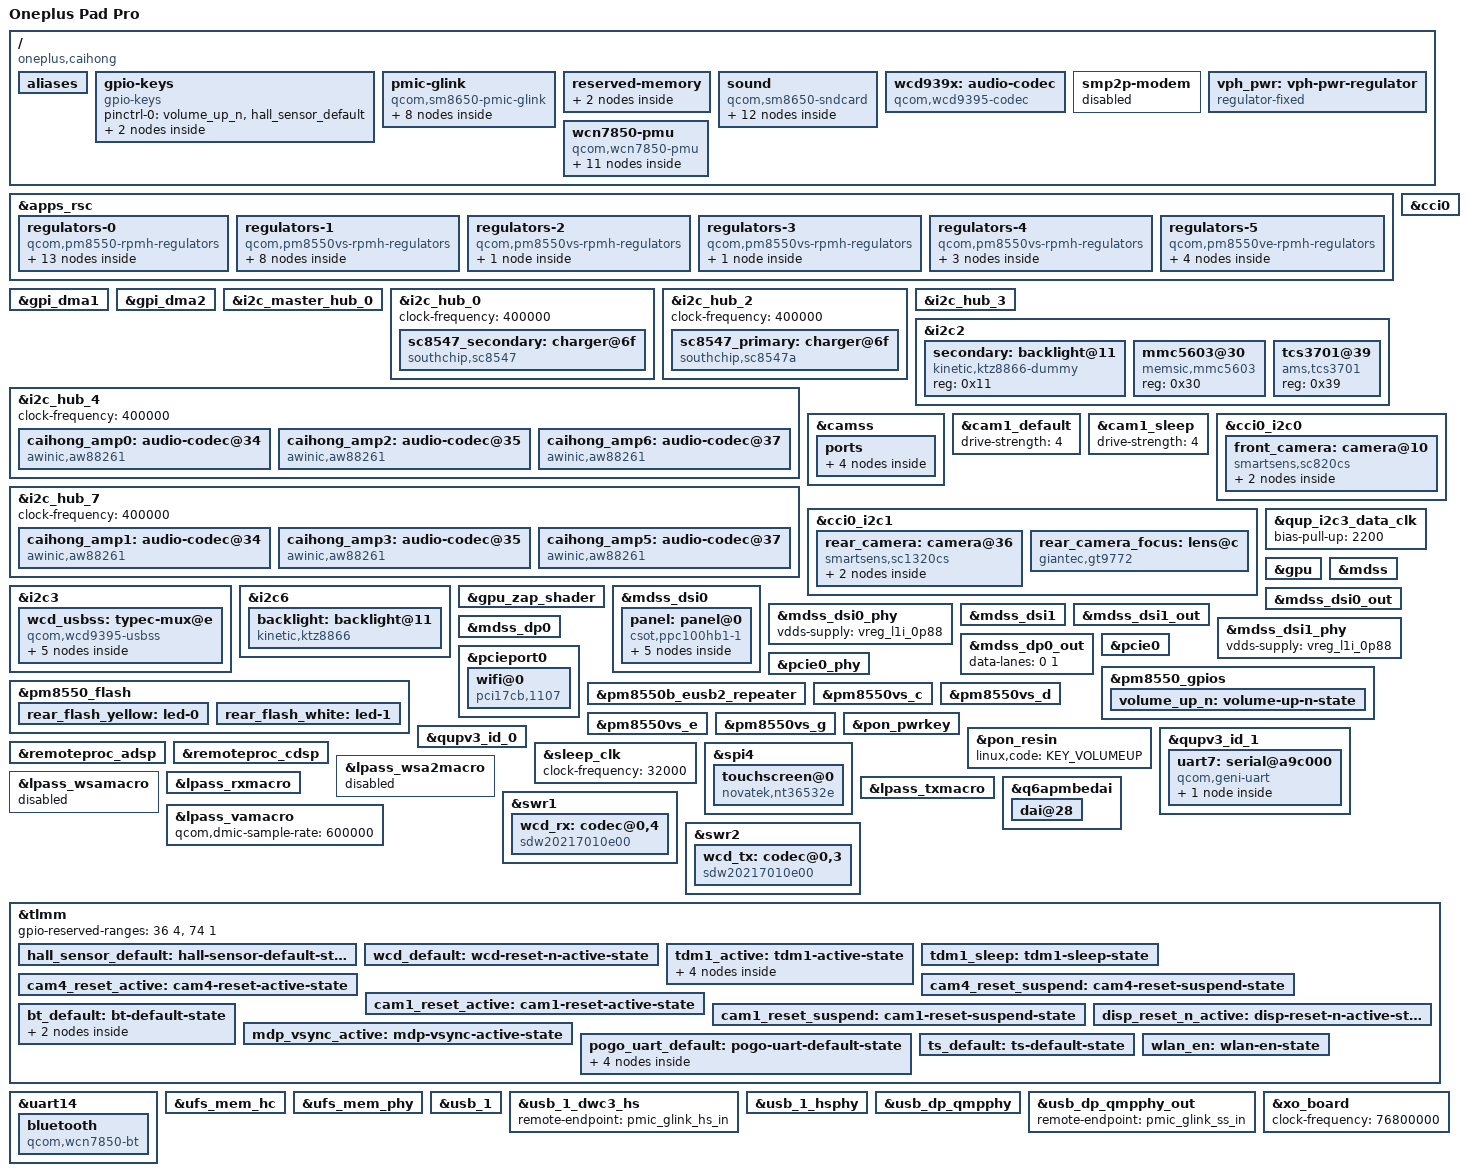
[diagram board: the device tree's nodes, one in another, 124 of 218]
// SPDX-License-Identifier: BSD-3-Clause
/*
 * Based on Qualcomm Reference Device DeviceTree
 *
 * Copyright (c) 2023, Linaro Limited
 * Copyright (c) 2025, 2026 Pengyu Luo <mitltlatltl@gmail.com>
 * Copyright (c) 2026 Osilvfe <osilvfe@gmail.com>
 */

/dts-v1/;

#include <dt-bindings/regulator/qcom,rpmh-regulator.h>
#include <dt-bindings/clock/qcom,sm8650-camcc.h>
#include <dt-bindings/gpio/gpio.h>
#include <dt-bindings/leds/common.h>
#include <dt-bindings/sound/qcom,q6dsp-lpass-ports.h>
#include "sm8650.dtsi"
#include "pm8550.dtsi"
#include "pm8550b.dtsi"
#define PMK8550VE_SID 8
#include "pm8550ve.dtsi"
#include "pm8550vs.dtsi"
#include "pmk8550.dtsi"

/* override */
/delete-node/ &adspslpi_mem;
/delete-node/ &hwfence_shbuf;

/* reusable */
/delete-node/ &trust_ui_vm_mem;
/delete-node/ &oem_vm_mem;
/delete-node/ &qdss_mem;

/ {
	model = "Oneplus Pad Pro";
	compatible = "oneplus,caihong", "qcom,sm8650";
	chassis-type = "tablet";

	aliases {
		serial1 = &uart14;
		serial5 = &uart7;
	};

	gpio-keys {
		compatible = "gpio-keys";

		pinctrl-0 = <&volume_up_n>, <&hall_sensor_default>;
		pinctrl-names = "default";

		key-volume-up {
			label = "Volume Up";
			linux,code = <KEY_VOLUMEDOWN>;
			gpios = <&pm8550_gpios 6 GPIO_ACTIVE_LOW>;
			debounce-interval = <15>;
			linux,can-disable;
			wakeup-source;
		};

		event-hall-sensor {
			label = "BU52053NVX Hall Switch";
			gpios = <&tlmm 66 GPIO_ACTIVE_LOW>;
			linux,input-type = <EV_SW>;
			linux,code = <SW_LID>;
			linux,can-disable;
			wakeup-source;
		};
	};

	pmic-glink {
		compatible = "qcom,sm8650-pmic-glink",
			     "qcom,sm8550-pmic-glink",
			     "qcom,pmic-glink";
		#address-cells = <1>;
		#size-cells = <0>;
		orientation-gpios = <&tlmm 29 GPIO_ACTIVE_HIGH>;
		oneplus,pps-read-buffer;
		oneplus,pps-auto-start;
		oneplus,otg-ap-control;
		oneplus,battery-current-inverted;
		oneplus,report-full-at-100;
		oneplus,power-now-from-vi;
		oneplus,ui-soc-smoothing;
		oneplus,ffc-policy;

		connector@0 {
			compatible = "usb-c-connector";
			reg = <0>;

			power-role = "dual";
			data-role = "dual";

			ports {
				#address-cells = <1>;
				#size-cells = <0>;

				port@0 {
					reg = <0>;

					pmic_glink_hs_in: endpoint {
						remote-endpoint = <&usb_1_dwc3_hs>;
					};
				};

				port@1 {
					reg = <1>;

					pmic_glink_ss_in: endpoint {
						remote-endpoint = <&usb_dp_qmpphy_out>;
					};
				};

				port@2 {
					reg = <2>;

					pmic_glink_sbu: endpoint {
						remote-endpoint = <&wcd_usbss_sbu_mux>;
					};
				};
			};
		};
	};

	reserved-memory {
		adspslpi_mem: adspslpi@9df00000 {
			reg = <0 0x9df00000 0 0x5280000>;
			no-map;
		};

		hwfence_shbuf: hwfence-shbuf@d4e23000 {
			reg = <0 0xd4e23000 0 0x2dd000>;
			no-map;
		};
	};

	sound {
		compatible = "qcom,sm8650-sndcard", "qcom,sm8450-sndcard";
		model = "SM8650-MTP";
		audio-routing = "IN1_HPHL", "HPHL_OUT",
				"IN2_HPHR", "HPHR_OUT",
				"AMIC1", "MIC BIAS1",
				"AMIC3", "MIC BIAS3",
				"AMIC4", "MIC BIAS4",
				"AMIC5", "MIC BIAS3",
				"TX SWR_INPUT0", "ADC1_OUTPUT",
				"TX SWR_INPUT1", "ADC2_OUTPUT",
				"TX SWR_INPUT2", "ADC3_OUTPUT",
				"TX SWR_INPUT3", "ADC4_OUTPUT";

		wcd-playback-dai-link {
			link-name = "WCD Playback";

			cpu {
				sound-dai = <&q6apmbedai RX_CODEC_DMA_RX_0>;
			};

			codec {
				sound-dai = <&wcd939x 0>, <&swr1 0>, <&lpass_rxmacro 0>;
			};

			platform {
				sound-dai = <&q6apm>;
			};
		};

		wcd-capture-dai-link {
			link-name = "WCD Capture";

			cpu {
				sound-dai = <&q6apmbedai TX_CODEC_DMA_TX_3>;
			};

			codec {
				sound-dai = <&wcd939x 1>, <&swr2 0>, <&lpass_txmacro 0>;
			};

			platform {
				sound-dai = <&q6apm>;
			};
		};

		tdm-speaker-dai-link {
			link-name = "Secondary TDM Speakers";

			cpu {
				sound-dai = <&q6apmbedai SECONDARY_TDM_RX_0>;
			};

			codec {
				sound-dai = <&caihong_amp0>, <&caihong_amp1>,
					    <&caihong_amp2>, <&caihong_amp3>,
					    <&caihong_amp5>, <&caihong_amp6>;
			};

			platform {
				sound-dai = <&q6apm>;
			};
		};
	};

	wcd939x: audio-codec {
		compatible = "qcom,wcd9395-codec", "qcom,wcd9390-codec";

		pinctrl-0 = <&wcd_default>;
		pinctrl-names = "default";

		qcom,micbias1-microvolt = <1800000>;
		qcom,micbias2-microvolt = <1800000>;
		qcom,micbias3-microvolt = <1800000>;
		qcom,micbias4-microvolt = <1800000>;
		qcom,mbhc-buttons-vthreshold-microvolt = <75000 150000 237000 500000
							 500000 500000 500000 500000>;
		qcom,mbhc-headset-vthreshold-microvolt = <1700000>;
		qcom,mbhc-headphone-vthreshold-microvolt = <50000>;
		qcom,rx-device = <&wcd_rx>;
		qcom,tx-device = <&wcd_tx>;

		reset-gpios = <&tlmm 107 GPIO_ACTIVE_LOW>;

		vdd-buck-supply = <&vreg_l15b_1p8>;
		vdd-rxtx-supply = <&vreg_l15b_1p8>;
		vdd-io-supply = <&vreg_l15b_1p8>;
		vdd-mic-bias-supply = <&vreg_bob1>;

		#sound-dai-cells = <1>;

	};

	smp2p-modem {
		status = "disabled";
	};

	vph_pwr: vph-pwr-regulator {
		compatible = "regulator-fixed";

		regulator-name = "vph_pwr";
		regulator-min-microvolt = <3700000>;
		regulator-max-microvolt = <3700000>;

		regulator-always-on;
		regulator-boot-on;
	};

	wcn7850-pmu {
		compatible = "qcom,wcn7850-pmu";

		pinctrl-names = "default";
		pinctrl-0 = <&wlan_en>, <&bt_default>;

		wlan-enable-gpios = <&tlmm 16 GPIO_ACTIVE_HIGH>;
		bt-enable-gpios = <&tlmm 17 GPIO_ACTIVE_HIGH>;

		vdd-supply = <&vreg_s4i_0p85>;
		vddio-supply = <&vreg_l15b_1p8>;
		vddio1p2-supply = <&vreg_l3c_1p2>;
		vddaon-supply = <&vreg_s2c_0p8>;
		vdddig-supply = <&vreg_s3c_0p9>;
		vddrfa1p2-supply = <&vreg_s1c_1p2>;
		vddrfa1p8-supply = <&vreg_s6c_1p8>;

		clocks = <&rpmhcc RPMH_RF_CLK1>;

		regulators {
			vreg_pmu_rfa_cmn: ldo0 {
				regulator-name = "vreg_pmu_rfa_cmn";
			};

			vreg_pmu_aon_0p59: ldo1 {
				regulator-name = "vreg_pmu_aon_0p59";
			};

			vreg_pmu_wlcx_0p8: ldo2 {
				regulator-name = "vreg_pmu_wlcx_0p8";
			};

			vreg_pmu_wlmx_0p85: ldo3 {
				regulator-name = "vreg_pmu_wlmx_0p85";
			};

			vreg_pmu_btcmx_0p85: ldo4 {
				regulator-name = "vreg_pmu_btcmx_0p85";
			};

			vreg_pmu_rfa_0p8: ldo5 {
				regulator-name = "vreg_pmu_rfa_0p8";
			};

			vreg_pmu_rfa_1p2: ldo6 {
				regulator-name = "vreg_pmu_rfa_1p2";
			};

			vreg_pmu_rfa_1p8: ldo7 {
				regulator-name = "vreg_pmu_rfa_1p8";
			};

			vreg_pmu_pcie_0p9: ldo8 {
				regulator-name = "vreg_pmu_pcie_0p9";
			};

			vreg_pmu_pcie_1p8: ldo9 {
				regulator-name = "vreg_pmu_pcie_1p8";
			};
		};
	};
};

&apps_rsc {
	regulators-0 {
		compatible = "qcom,pm8550-rpmh-regulators";

		vdd-bob1-supply = <&vph_pwr>;
		vdd-bob2-supply = <&vph_pwr>;
		vdd-l2-l13-l14-supply = <&vreg_bob1>;
		vdd-l3-supply = <&vreg_s1c_1p2>;
		vdd-l5-l16-supply = <&vreg_bob1>;
		vdd-l6-l7-supply = <&vreg_bob1>;
		vdd-l8-l9-supply = <&vreg_bob1>;
		vdd-l11-supply = <&vreg_s1c_1p2>;
		vdd-l12-supply = <&vreg_s6c_1p8>;
		vdd-l15-supply = <&vreg_s6c_1p8>;
		vdd-l17-supply = <&vreg_bob2>;

		qcom,pmic-id = "b";

		vreg_bob1: bob1 {
			regulator-name = "vreg_bob1";
			regulator-min-microvolt = <3296000>;
			regulator-max-microvolt = <3960000>;
			regulator-initial-mode = <RPMH_REGULATOR_MODE_HPM>;
		};

		vreg_bob2: bob2 {
			regulator-name = "vreg_bob2";
			regulator-min-microvolt = <2720000>;
			regulator-max-microvolt = <3008000>;
			regulator-initial-mode = <RPMH_REGULATOR_MODE_HPM>;
		};

		vreg_l2b_3p0: ldo2 {
			regulator-name = "vreg_l2b_3p0";
			regulator-min-microvolt = <3008000>;
			regulator-max-microvolt = <3008000>;
			regulator-initial-mode = <RPMH_REGULATOR_MODE_HPM>;
			regulator-allow-set-load;
			regulator-allowed-modes = <RPMH_REGULATOR_MODE_LPM
						   RPMH_REGULATOR_MODE_HPM>;
		};

		vreg_l4b_1p8: ldo4 { /* rear and front cam */
			regulator-name = "vreg_l4b_1p8";
			regulator-min-microvolt = <1800000>;
			regulator-max-microvolt = <1800000>;
			regulator-initial-mode = <RPMH_REGULATOR_MODE_HPM>;
			regulator-allow-set-load;
			regulator-allowed-modes = <RPMH_REGULATOR_MODE_LPM
						   RPMH_REGULATOR_MODE_HPM>;
		};

		vreg_l5b_3p1: ldo5 {
			regulator-name = "vreg_l5b_3p1";
			regulator-min-microvolt = <3104000>;
			regulator-max-microvolt = <3104000>;
			regulator-initial-mode = <RPMH_REGULATOR_MODE_HPM>;
			regulator-allow-set-load;
			regulator-allowed-modes = <RPMH_REGULATOR_MODE_LPM
						   RPMH_REGULATOR_MODE_HPM>;
		};

		vreg_l9b_2p8: ldo9 { /* cam */
			regulator-name = "vreg_l9b_2p8";
			regulator-min-microvolt = <2800000>;
			regulator-max-microvolt = <2800000>;
			regulator-initial-mode = <RPMH_REGULATOR_MODE_HPM>;
			regulator-allow-set-load;
			regulator-allowed-modes = <RPMH_REGULATOR_MODE_LPM
						   RPMH_REGULATOR_MODE_HPM>;
		};

		vreg_l10b_1p8: ldo10 {
			regulator-name = "vreg_l10b_1p8";
			regulator-min-microvolt = <1800000>;
			regulator-max-microvolt = <1800000>;
			regulator-initial-mode = <RPMH_REGULATOR_MODE_HPM>;
			regulator-allow-set-load;
			regulator-allowed-modes = <RPMH_REGULATOR_MODE_LPM
						   RPMH_REGULATOR_MODE_HPM>;
		};

		vreg_l11b_1p2: ldo11 {
			regulator-name = "vreg_l11b_1p2";
			regulator-min-microvolt = <1200000>;
			regulator-max-microvolt = <1200000>;
			regulator-initial-mode = <RPMH_REGULATOR_MODE_HPM>;
			regulator-allow-set-load;
			regulator-allowed-modes = <RPMH_REGULATOR_MODE_LPM
						   RPMH_REGULATOR_MODE_HPM>;
		};

		vreg_l12b_1p8: ldo12 {
			regulator-name = "vreg_l12b_1p8";
			regulator-min-microvolt = <1800000>;
			regulator-max-microvolt = <1800000>;
			regulator-initial-mode = <RPMH_REGULATOR_MODE_HPM>;
			regulator-allow-set-load;
			regulator-allowed-modes = <RPMH_REGULATOR_MODE_LPM
						   RPMH_REGULATOR_MODE_HPM>;
		};

		vreg_l13b_3p0: ldo13 {
			regulator-name = "vreg_l13b_3p0";
			regulator-min-microvolt = <3000000>;
			regulator-max-microvolt = <3200000>;
			regulator-initial-mode = <RPMH_REGULATOR_MODE_HPM>;
			regulator-allow-set-load;
			regulator-allowed-modes = <RPMH_REGULATOR_MODE_LPM
						   RPMH_REGULATOR_MODE_HPM>;
		};

		vreg_l15b_1p8: ldo15 {
			regulator-name = "vreg_l15b_1p8";
			regulator-min-microvolt = <1800000>;
			regulator-max-microvolt = <1800000>;
			regulator-initial-mode = <RPMH_REGULATOR_MODE_HPM>;
			regulator-allow-set-load;
			regulator-allowed-modes = <RPMH_REGULATOR_MODE_LPM
						   RPMH_REGULATOR_MODE_HPM>;
		};

		vreg_l16b_2p8: ldo16 { /* cam */
			regulator-name = "vreg_l16b_2p8";
			regulator-min-microvolt = <2800000>;
			regulator-max-microvolt = <2800000>;
			regulator-initial-mode = <RPMH_REGULATOR_MODE_HPM>;
			regulator-allow-set-load;
			regulator-allowed-modes = <RPMH_REGULATOR_MODE_LPM
						   RPMH_REGULATOR_MODE_HPM>;
		};

		vreg_l17b_2p5: ldo17 {
			regulator-name = "vreg_l17b_2p5";
			regulator-min-microvolt = <2504000>;
			regulator-max-microvolt = <2504000>;
			regulator-initial-mode = <RPMH_REGULATOR_MODE_HPM>;
			regulator-allow-set-load;
			regulator-allowed-modes = <RPMH_REGULATOR_MODE_LPM
						   RPMH_REGULATOR_MODE_HPM>;
		};
	};

	regulators-1 {
		compatible = "qcom,pm8550vs-rpmh-regulators";

		vdd-l1-supply = <&vreg_s1c_1p2>;
		vdd-l2-supply = <&vreg_s1c_1p2>;
		vdd-l3-supply = <&vreg_s1c_1p2>;
		vdd-s1-supply = <&vph_pwr>;
		vdd-s2-supply = <&vph_pwr>;
		vdd-s3-supply = <&vph_pwr>;
		vdd-s4-supply = <&vph_pwr>;
		vdd-s5-supply = <&vph_pwr>;
		vdd-s6-supply = <&vph_pwr>;

		qcom,pmic-id = "c";

		vreg_s1c_1p2: smps1 {
			regulator-name = "vreg_s1c_1p2";
			regulator-min-microvolt = <1256000>;
			regulator-max-microvolt = <1348000>;
			regulator-initial-mode = <RPMH_REGULATOR_MODE_HPM>;
		};

		vreg_s2c_0p8: smps2 {
			regulator-name = "vreg_s2c_0p8";
			regulator-min-microvolt = <852000>;
			regulator-max-microvolt = <1036000>;
			regulator-initial-mode = <RPMH_REGULATOR_MODE_HPM>;
		};

		vreg_s3c_0p9: smps3 {
			regulator-name = "vreg_s3c_0p9";
			regulator-min-microvolt = <976000>;
			regulator-max-microvolt = <1064000>;
			regulator-initial-mode = <RPMH_REGULATOR_MODE_HPM>;
		};

		vreg_s4c_1p2: smps4 {
			regulator-name = "vreg_s4c_1p2";
			regulator-min-microvolt = <1224000>;
			regulator-max-microvolt = <1280000>;
			regulator-initial-mode = <RPMH_REGULATOR_MODE_HPM>;
		};

		vreg_s5c_0p7: smps5 {
			regulator-name = "vreg_s5c_0p7";
			regulator-min-microvolt = <752000>;
			regulator-max-microvolt = <900000>;
			regulator-initial-mode = <RPMH_REGULATOR_MODE_HPM>;
		};

		vreg_s6c_1p8: smps6 {
			regulator-name = "vreg_s6c_1p8";
			regulator-min-microvolt = <1856000>;
			regulator-max-microvolt = <2000000>;
			regulator-initial-mode = <RPMH_REGULATOR_MODE_HPM>;
		};

		vreg_l1c_1p2: ldo1 {
			regulator-name = "vreg_l1c_1p2";
			regulator-min-microvolt = <1200000>;
			regulator-max-microvolt = <1200000>;
			regulator-initial-mode = <RPMH_REGULATOR_MODE_HPM>;
			regulator-allow-set-load;
			regulator-allowed-modes = <RPMH_REGULATOR_MODE_LPM
						   RPMH_REGULATOR_MODE_HPM>;
		};

		vreg_l3c_1p2: ldo3 {
			regulator-name = "vreg_l3c_1p2";
			regulator-min-microvolt = <1200000>;
			regulator-max-microvolt = <1200000>;
			regulator-initial-mode = <RPMH_REGULATOR_MODE_HPM>;
			regulator-allow-set-load;
			regulator-allowed-modes = <RPMH_REGULATOR_MODE_LPM
						   RPMH_REGULATOR_MODE_HPM>;
		};
	};

	regulators-2 {
		compatible = "qcom,pm8550vs-rpmh-regulators";

		vdd-l1-supply = <&vreg_s3c_0p9>;

		qcom,pmic-id = "d";

		vreg_l1d_0p88: ldo1 {
			regulator-name = "vreg_l1d_0p88";
			regulator-min-microvolt = <912000>;
			regulator-max-microvolt = <920000>;
			regulator-initial-mode = <RPMH_REGULATOR_MODE_HPM>;
			regulator-allow-set-load;
			regulator-allowed-modes = <RPMH_REGULATOR_MODE_LPM
						   RPMH_REGULATOR_MODE_HPM>;
		};
	};

	regulators-3 {
		compatible = "qcom,pm8550vs-rpmh-regulators";

		vdd-l3-supply = <&vreg_s3c_0p9>;

		qcom,pmic-id = "e";

		vreg_l3e_0p9: ldo3 {
			regulator-name = "vreg_l3e_0p9";
			regulator-min-microvolt = <880000>;
			regulator-max-microvolt = <920000>;
			regulator-initial-mode = <RPMH_REGULATOR_MODE_HPM>;
			regulator-allow-set-load;
			regulator-allowed-modes = <RPMH_REGULATOR_MODE_LPM
						   RPMH_REGULATOR_MODE_HPM>;
		};
	};

	regulators-4 {
		compatible = "qcom,pm8550vs-rpmh-regulators";

		vdd-l1-supply = <&vreg_s3c_0p9>;
		vdd-l3-supply = <&vreg_s3c_0p9>;

		qcom,pmic-id = "g";

		vreg_l1g_0p91: ldo1 {
			regulator-name = "vreg_l1g_0p91";
			regulator-min-microvolt = <912000>;
			regulator-max-microvolt = <920000>;
			regulator-initial-mode = <RPMH_REGULATOR_MODE_HPM>;
			regulator-allow-set-load;
			regulator-allowed-modes = <RPMH_REGULATOR_MODE_LPM
						   RPMH_REGULATOR_MODE_HPM>;
		};

		vreg_l2g_1p2: ldo2 { /* cam */
			regulator-name = "vreg_l2g_1p2";
			regulator-min-microvolt = <1200000>;
			regulator-max-microvolt = <1200000>;
			regulator-initial-mode = <RPMH_REGULATOR_MODE_HPM>;
			regulator-allow-set-load;
			regulator-allowed-modes = <RPMH_REGULATOR_MODE_LPM
						   RPMH_REGULATOR_MODE_HPM>;
		};

		vreg_l3g_0p91: ldo3 {
			regulator-name = "vreg_l3g_0p91";
			regulator-min-microvolt = <880000>;
			regulator-max-microvolt = <912000>;
			regulator-initial-mode = <RPMH_REGULATOR_MODE_HPM>;
			regulator-allow-set-load;
			regulator-allowed-modes = <RPMH_REGULATOR_MODE_LPM
						   RPMH_REGULATOR_MODE_HPM>;
		};
	};

	regulators-5 {
		compatible = "qcom,pm8550ve-rpmh-regulators";

		vdd-l1-supply = <&vreg_s3c_0p9>;
		vdd-l2-supply = <&vreg_s3c_0p9>;
		vdd-l3-supply = <&vreg_s1c_1p2>;
		vdd-s4-supply = <&vph_pwr>;

		qcom,pmic-id = "i";

		vreg_s4i_0p85: smps4 {
			regulator-name = "vreg_s4i_0p85";
			regulator-min-microvolt = <852000>;
			regulator-max-microvolt = <1004000>;
			regulator-initial-mode = <RPMH_REGULATOR_MODE_HPM>;
		};

		vreg_l1i_0p88: ldo1 {
			regulator-name = "vreg_l1i_0p88";
			regulator-min-microvolt = <880000>;
			regulator-max-microvolt = <912000>;
			regulator-initial-mode = <RPMH_REGULATOR_MODE_HPM>;
			regulator-allow-set-load;
			regulator-allowed-modes = <RPMH_REGULATOR_MODE_LPM
						   RPMH_REGULATOR_MODE_HPM>;
		};

		vreg_l2i_0p88: ldo2 {
			regulator-name = "vreg_l2i_0p88";
			regulator-min-microvolt = <880000>;
			regulator-max-microvolt = <912000>;
			regulator-initial-mode = <RPMH_REGULATOR_MODE_HPM>;
			regulator-allow-set-load;
			regulator-allowed-modes = <RPMH_REGULATOR_MODE_LPM
						   RPMH_REGULATOR_MODE_HPM>;
		};

		vreg_l3i_1p2: ldo3 {
			regulator-name = "vreg_l3i_0p91";
			regulator-min-microvolt = <1200000>;
			regulator-max-microvolt = <1200000>;
			regulator-initial-mode = <RPMH_REGULATOR_MODE_HPM>;
			regulator-allow-set-load;
			regulator-allowed-modes = <RPMH_REGULATOR_MODE_LPM
						   RPMH_REGULATOR_MODE_HPM>;
		};
	};
};

&gpi_dma1 {
	status = "okay";
};

&gpi_dma2 {
	status = "okay";
};

&i2c_master_hub_0 {
	status = "okay";
};

&i2c_hub_0 {
	clock-frequency = <400000>;

	status = "okay";

	sc8547_secondary: charger@6f {
		compatible = "southchip,sc8547";
		reg = <0x6f>;
		southchip,role = "secondary";
	};
};

&i2c_hub_2 {
	clock-frequency = <400000>;

	status = "okay";

	sc8547_primary: charger@6f {
		compatible = "southchip,sc8547a";
		reg = <0x6f>;
		southchip,role = "primary";
	};
};

&i2c_hub_3 {
	status = "okay";

	// pencil-wireless-charger@41
};

&i2c_hub_4 {
	clock-frequency = <400000>;

	status = "okay";

	caihong_amp0: audio-codec@34 {
		compatible = "awinic,aw88261";
		reg = <0x34>;
		#sound-dai-cells = <0>;
		dvdd-supply = <&vreg_l15b_1p8>;
		firmware-name = "awinic/caihong-aw88261-acf.bin";
		awinic,audio-channel = <0>;
		awinic,sync-flag;
		sound-name-prefix = "Amp0";
	};

	caihong_amp2: audio-codec@35 {
		compatible = "awinic,aw88261";
		reg = <0x35>;
		#sound-dai-cells = <0>;
		dvdd-supply = <&vreg_l15b_1p8>;
		firmware-name = "awinic/caihong-aw88261-acf.bin";
		awinic,audio-channel = <2>;
		awinic,sync-flag;
		sound-name-prefix = "Amp2";
	};

	caihong_amp6: audio-codec@37 {
		compatible = "awinic,aw88261";
		reg = <0x37>;
		#sound-dai-cells = <0>;
		dvdd-supply = <&vreg_l15b_1p8>;
		firmware-name = "awinic/caihong-aw88261-acf.bin";
		awinic,audio-channel = <6>;
		awinic,sync-flag;
		sound-name-prefix = "Amp6";
	};
};

&i2c_hub_7 {
	clock-frequency = <400000>;

	status = "okay";

	caihong_amp1: audio-codec@34 {
		compatible = "awinic,aw88261";
		reg = <0x34>;
		#sound-dai-cells = <0>;
		dvdd-supply = <&vreg_l15b_1p8>;
		firmware-name = "awinic/caihong-aw88261-acf.bin";
		awinic,audio-channel = <1>;
		awinic,sync-flag;
		sound-name-prefix = "Amp1";
	};

	caihong_amp3: audio-codec@35 {
		compatible = "awinic,aw88261";
		reg = <0x35>;
		#sound-dai-cells = <0>;
		dvdd-supply = <&vreg_l15b_1p8>;
		firmware-name = "awinic/caihong-aw88261-acf.bin";
		awinic,audio-channel = <3>;
		awinic,sync-flag;
		sound-name-prefix = "Amp3";
	};

	caihong_amp5: audio-codec@37 {
		compatible = "awinic,aw88261";
		reg = <0x37>;
		#sound-dai-cells = <0>;
		dvdd-supply = <&vreg_l15b_1p8>;
		firmware-name = "awinic/caihong-aw88261-acf.bin";
		awinic,audio-channel = <5>;
		awinic,sync-flag;
		sound-name-prefix = "Amp5";
	};
};

&i2c2 {
	status = "okay";

	secondary: backlight@11 {
		/*
		 * The i2c controller will set this node as a i2c client if
		 * compatible is present
		 */
		compatible = "kinetic,ktz8866-dummy";
		reg = <0x11>;
	};

	/* Registry-confirmed I2C2 sensor addresses for controlled AP probing. */
	mmc5603@30 {
		compatible = "memsic,mmc5603";
		reg = <0x30>;
		status = "okay";
	};

	tcs3701@39 {
		compatible = "ams,tcs3701";
		reg = <0x39>;
		status = "okay";
	};
};

/*
 * Mainline camera bring-up. The downstream Caihong overlay connects the rear
 * SC1320CS to CSIPHY1 and the front SC820CS to CSIPHY4.
 */
&camss {
	/* SM8650 CAMSS groups CSIPHY0/1 on the shared 01 rail pair. */
	vdd-csiphy01-0p9-supply = <&vreg_l2i_0p88>;
	vdd-csiphy01-1p2-supply = <&vreg_l3i_1p2>;
	/* SM8650 CAMSS groups CSIPHY2/4 on the shared 24 rail pair. */
	vdd-csiphy24-0p9-supply = <&vreg_l2i_0p88>;
	vdd-csiphy24-1p2-supply = <&vreg_l3i_1p2>;
	status = "okay";

	ports {
		port@1 {
			reg = <1>;

			caihong_csiphy1_ep: endpoint {
				data-lanes = <0 1 2 3>;
				remote-endpoint = <&caihong_rear_cam_ep>;
			};
		};

		port@4 {
			reg = <4>;

			caihong_csiphy4_ep: endpoint {
				data-lanes = <0 1 2 3>;
				remote-endpoint = <&caihong_front_cam_ep>;
			};
		};
	};
};

/* Caihong's downstream overlay drives the rear MCLK1 pin at 4 mA. */
&cam1_default {
	drive-strength = <4>;
};

&cam1_sleep {
	drive-strength = <4>;
};

&cci0 {
	status = "okay";
};

&cci0_i2c0 {
	#address-cells = <1>;
	#size-cells = <0>;
	clock-frequency = <400000>;
	/* The downstream Caihong CCI timing enables SCL clock stretching. */
	hw-scl-stretch-en = <1>;

	/* Hardware probe while powered: SC820CS responds at Linux address 0x10. */
	front_camera: camera@10 {
		compatible = "smartsens,sc820cs";
		reg = <0x10>;
		orientation = <0>;
		rotation = <180>;

		clocks = <&camcc CAM_CC_MCLK4_CLK>;
		clock-names = "xvclk";
		assigned-clocks = <&camcc CAM_CC_MCLK4_CLK>;
		assigned-clock-rates = <19200000>;
		power-domains = <&camcc CAM_CC_TITAN_TOP_GDSC>;

		reset-gpios = <&tlmm 7 GPIO_ACTIVE_LOW>;
		pinctrl-0 = <&cam4_default>, <&cam4_reset_active>;
		pinctrl-1 = <&cam4_sleep>, <&cam4_reset_suspend>;
		/* The generic Linux pinctrl core selects the standard default state. */
		pinctrl-names = "default", "sleep";

		dovdd-supply = <&vreg_l4b_1p8>;
		avdd-supply = <&vreg_l16b_2p8>;
		dvdd-supply = <&vreg_l2g_1p2>;

		port {
			caihong_front_cam_ep: endpoint {
				clock-lanes = <7>;
				data-lanes = <0 1 2 3>;
				link-frequencies = /bits/ 64 <366000000>;
				remote-endpoint = <&caihong_csiphy4_ep>;
			};
		};
	};
};

/*
 * Rear SC1320CS bring-up. Read-only hardware probing confirmed the sensor at
 * Linux 7-bit address 0x36; the module keeps a small fallback list for board
 * revisions but starts from this confirmed DT address.
 */
&cci0_i2c1 {
	#address-cells = <1>;
	#size-cells = <0>;
	clock-frequency = <400000>;
	hw-scl-stretch-en = <1>;

	rear_camera: camera@36 {
		compatible = "smartsens,sc1320cs";
		reg = <0x36>;
		orientation = <1>;
		rotation = <180>;
		lens-focus = <&rear_camera_focus>;
		flash-leds = <&rear_flash_yellow>, <&rear_flash_white>;

		clocks = <&camcc CAM_CC_MCLK1_CLK>;
		clock-names = "xvclk";
		assigned-clocks = <&camcc CAM_CC_MCLK1_CLK>;
		assigned-clock-rates = <19200000>;
		power-domains = <&camcc CAM_CC_TITAN_TOP_GDSC>;

		reset-gpios = <&tlmm 82 GPIO_ACTIVE_LOW>;
		pinctrl-0 = <&cam1_default>, <&cam1_reset_active>;
		pinctrl-1 = <&cam1_sleep>, <&cam1_reset_suspend>;
		pinctrl-names = "default", "sleep";

		dovdd-supply = <&vreg_l4b_1p8>;
		avdd-supply = <&vreg_l16b_2p8>;
		dvdd-supply = <&vreg_l2g_1p2>;

		port {
			caihong_rear_cam_ep: endpoint {
				clock-lanes = <7>;
				data-lanes = <0 1 2 3>;
				link-frequencies = /bits/ 64 <600000000>;
				remote-endpoint = <&caihong_csiphy1_ep>;
			};
		};
	};

	rear_camera_focus: lens@c {
		compatible = "giantec,gt9772";
		reg = <0x0c>;

		vio-supply = <&vreg_l4b_1p8>;
		vaf-supply = <&vreg_l9b_2p8>;
	};
};

// qrd use this ?
&qup_i2c3_data_clk {
	/* Use internal I2C pull-up */
	bias-pull-up = <2200>;
};

&i2c3 {
	status = "okay";

	wcd_usbss: typec-mux@e {
		compatible = "qcom,wcd9395-usbss", "qcom,wcd9390-usbss";
		reg = <0xe>;
		qcom,vooc-dpdm-switch;

		vdd-supply = <&vreg_l15b_1p8>;
		// reset-gpios = <&tlmm 152 GPIO_ACTIVE_HIGH>; // ?

		mode-switch;
		orientation-switch;

		ports {
			#address-cells = <1>;
			#size-cells = <0>;

			port@0 {
				reg = <0>;

				wcd_usbss_sbu_mux: endpoint {
					remote-endpoint = <&pmic_glink_sbu>;
				};
			};

			port@1 {
				reg = <1>;

				wcd_usbss_headset_out: endpoint {};
			};
		};
	};
};

&i2c6 {
	status = "okay";

	backlight: backlight@11 {
		compatible = "kinetic,ktz8866";
		reg = <0x11>;

		enable-gpios = <&tlmm 89 GPIO_ACTIVE_HIGH>;
		enp-gpios = <&tlmm 90 GPIO_ACTIVE_HIGH>;
		enn-gpios = <&tlmm 91 GPIO_ACTIVE_HIGH>;

		secondary = <&secondary>;
	};
};

&gpu {
	status = "okay";
};

&gpu_zap_shader {
	firmware-name = "qcom/sm8650/Oneplus/caihong/gen70900_zap.mbn";
};

&mdss {
	status = "okay";
};

&mdss_dsi0 {
	vdda-supply = <&vreg_l3i_1p2>;

	qcom,dual-dsi-mode;
	qcom,sync-dual-dsi;
	qcom,master-dsi;

	status = "okay";

	panel: panel@0 {
		compatible = "csot,ppc100hb1-1";
		reg = <0>;

		backlight = <&backlight>;

		reset-gpios = <&tlmm 133 GPIO_ACTIVE_LOW>;

		vddio-supply = <&vreg_l12b_1p8>;

		pinctrl-0 = <&disp_reset_n_active>, <&mdp_vsync_active>;
		pinctrl-names = "default";

		ports {
			#address-cells = <1>;
			#size-cells = <0>;

			port@0 {
				reg = <0>;

				panel_in_0: endpoint {
					remote-endpoint = <&mdss_dsi0_out>;
				};
			};

			port@1 {
				reg = <1>;

				panel_in_1: endpoint {
					remote-endpoint = <&mdss_dsi1_out>;
				};
			};
		};
	};
};

&mdss_dsi0_out {
	remote-endpoint = <&panel_in_0>;
	data-lanes = <0 1 2 3>;
};

&mdss_dsi0_phy {
	vdds-supply = <&vreg_l1i_0p88>;

	status = "okay";
};

&mdss_dsi1 {
	vdda-supply = <&vreg_l3i_1p2>;

	qcom,dual-dsi-mode;
	qcom,sync-dual-dsi;

	status = "okay";

	/* DSI1 is slave, so use DSI0 clocks */
	assigned-clock-parents = <&mdss_dsi0_phy DSI_BYTE_PLL_CLK>,
				 <&mdss_dsi0_phy DSI_PIXEL_PLL_CLK>;
};

&mdss_dsi1_out {
	remote-endpoint = <&panel_in_1>;
	data-lanes = <0 1 2 3>;
};

&mdss_dsi1_phy {
	vdds-supply = <&vreg_l1i_0p88>;

	status = "okay";
};

&mdss_dp0 {
	status = "okay";
};

&mdss_dp0_out {
	data-lanes = <0 1>;
};

&pcie0 {
	wake-gpios = <&tlmm 96 GPIO_ACTIVE_HIGH>;
	perst-gpios = <&tlmm 94 GPIO_ACTIVE_LOW>;

	pinctrl-0 = <&pcie0_default_state>;
	pinctrl-names = "default";

	status = "okay";
};

&pcieport0 {
	wifi@0 {
		compatible = "pci17cb,1107";
		reg = <0x10000 0x0 0x0 0x0 0x0>;
		firmware-name = "caihong";

		vddrfacmn-supply = <&vreg_pmu_rfa_cmn>;
		vddaon-supply = <&vreg_pmu_aon_0p59>;
		vddwlcx-supply = <&vreg_pmu_wlcx_0p8>;
		vddwlmx-supply = <&vreg_pmu_wlmx_0p85>;
		vddrfa0p8-supply = <&vreg_pmu_rfa_0p8>;
		vddrfa1p2-supply = <&vreg_pmu_rfa_1p2>;
		vddrfa1p8-supply = <&vreg_pmu_rfa_1p8>;
		vddpcie0p9-supply = <&vreg_pmu_pcie_0p9>;
		vddpcie1p8-supply = <&vreg_pmu_pcie_1p8>;
	};
};

&pcie0_phy {
	vdda-phy-supply = <&vreg_l1i_0p88>;
	vdda-pll-supply = <&vreg_l3i_1p2>;

	status = "okay";
};

&pm8550_gpios {
	volume_up_n: volume-up-n-state {
		pins = "gpio6";
		function = "normal";
		bias-pull-up;
		input-enable;
		power-source = <1>;
	};
};

&pm8550_flash {
	status = "okay";

	rear_flash_yellow: led-0 {
		function = LED_FUNCTION_FLASH;
		color = <LED_COLOR_ID_YELLOW>;
		led-sources = <1>;
		led-max-microamp = <500000>;
		flash-max-microamp = <1500000>;
		flash-max-timeout-us = <1280000>;
		function-enumerator = <0>;
	};

	rear_flash_white: led-1 {
		function = LED_FUNCTION_FLASH;
		color = <LED_COLOR_ID_WHITE>;
		led-sources = <2>;
		led-max-microamp = <500000>;
		flash-max-microamp = <1500000>;
		flash-max-timeout-us = <1280000>;
		function-enumerator = <1>;
	};
};

&pm8550b_eusb2_repeater {
	/* 0x51 */
	qcom,tune-usb2-amplitude = /bits/ 8 <0xd>;
	/* 0x53 */
	qcom,tune-usb2-disc-thres = /bits/ 8 <0x6>;
	/* 0x54 */
	qcom,tune-usb2-squelch = /bits/ 8 <0x6>;
	/* 0x57 */
	qcom,tune-usb2-preem = /bits/ 8 <0x3>;

	vdd18-supply = <&vreg_l15b_1p8>;
	vdd3-supply = <&vreg_l5b_3p1>;
};

&pm8550vs_c {
	status = "okay";
};

&pm8550vs_d {
	status = "okay";
};

&pm8550vs_e {
	status = "okay";
};

&pm8550vs_g {
	status = "okay";
};

&pon_pwrkey {
	status = "okay";
};

&pon_resin {
	linux,code = <KEY_VOLUMEUP>;

	status = "okay";
};

&qupv3_id_0 {
	status = "okay";
};

&qupv3_id_1 {
	status = "okay";

	uart7: serial@a9c000 {
		compatible = "qcom,geni-uart";
		reg = <0 0x00a9c000 0 0x4000>;
		interrupts = <GIC_SPI 579 IRQ_TYPE_LEVEL_HIGH 0>;
		clocks = <&gcc GCC_QUPV3_WRAP1_S7_CLK>;
		clock-names = "se";
		interconnects = <&clk_virt MASTER_QUP_CORE_1 QCOM_ICC_TAG_ALWAYS
				 &clk_virt SLAVE_QUP_CORE_1 QCOM_ICC_TAG_ALWAYS>,
				<&gem_noc MASTER_APPSS_PROC QCOM_ICC_TAG_ACTIVE_ONLY
				 &config_noc SLAVE_QUP_1 QCOM_ICC_TAG_ACTIVE_ONLY>;
		interconnect-names = "qup-core", "qup-config";
		power-domains = <&rpmhpd RPMHPD_CX>;
		operating-points-v2 = <&qup_opp_table_100mhz>;
		pinctrl-0 = <&pogo_uart_default>;
		pinctrl-names = "default";
		qcom,force-fifo-mode;
		status = "okay";

		keyboard {
			compatible = "oneplus,caihong-pogo";
			current-speed = <921600>;
			power-gpios = <&tlmm 100 GPIO_ACTIVE_HIGH>;
			wake-gpios = <&tlmm 137 GPIO_ACTIVE_LOW>;
			tx-enable-gpios = <&tlmm 14 GPIO_ACTIVE_HIGH>;
			touchpad-size-x = <2764>;
			touchpad-size-y = <1630>;
			touchpad-resolution-x = <23>;
			touchpad-resolution-y = <23>;
			oneplus,crc-ibm-init = <0xc596>;
		};
	};
};

&remoteproc_adsp {
	firmware-name = "qcom/sm8650/Oneplus/caihong/adsp.mbn",
			"qcom/sm8650/Oneplus/caihong/adsp_dtb.mbn";

	status = "okay";
};

&remoteproc_cdsp {
	firmware-name = "qcom/sm8650/Oneplus/caihong/cdsp.mbn",
			"qcom/sm8650/Oneplus/caihong/cdsp_dtb.mbn";

	status = "okay";
};

&sleep_clk {
	clock-frequency = <32000>;
};

&spi4 {
	status = "okay";

	touchscreen@0 {
		compatible = "novatek,nt36532e";
		reg = <0>;

		interrupts-extended = <&tlmm 162 IRQ_TYPE_EDGE_FALLING>;
		reset-gpios = <&tlmm 161 GPIO_ACTIVE_LOW>;

		spi-max-frequency = <12000000>;

		panel = <&panel>;
		novatek,pen-support;
		novatek,pen-max-pressure = <16383>;
		novatek,pen-max-tilt = <60>;
		firmware-name = "novatek/DT-novatek-nt36532.bin";

		// nvt_get_fw_info, from fw?
		touchscreen-size-x = <21200>;
		touchscreen-size-y = <30000>;
		touchscreen-max-pressure = <1000>;
		/* Raw touch axes precede the landscape swap below. */
		touchscreen-x-mm = <177>;
		touchscreen-y-mm = <250>;
		touchscreen-swapped-x-y;
		touchscreen-inverted-x;

		pinctrl-0 = <&ts_default>;
		pinctrl-names = "default";
	};
};

&lpass_wsa2macro {
	status = "disabled";
};

&lpass_wsamacro {
	status = "disabled";
};

&lpass_rxmacro {
	status = "okay";
};

&lpass_txmacro {
	status = "okay";
};

&lpass_vamacro {
	qcom,dmic-sample-rate = <600000>;
	status = "okay";
};

&q6apmbedai {
	#address-cells = <1>;
	#size-cells = <0>;

	pinctrl-0 = <&tdm1_active>;
	pinctrl-1 = <&tdm1_sleep>;
	pinctrl-names = "default", "sleep";

	dai@28 {
		reg = <SECONDARY_TDM_RX_0>;
		clocks = <&q6prmcc LPASS_CLK_ID_SEC_TDM_IBIT
				      LPASS_CLK_ATTRIBUTE_COUPLE_NO>;
		clock-names = "bclk";
	};
};

&swr1 {
	status = "okay";

	wcd_rx: codec@0,4 {
		compatible = "sdw20217010e00";
		reg = <0 4>;
		qcom,rx-port-mapping = <1 2 3 4 5 9>;
	};
};

&swr2 {
	status = "okay";

	wcd_tx: codec@0,3 {
		compatible = "sdw20217010e00";
		reg = <0 3>;
		qcom,tx-port-mapping = <2 2 3 4>;
	};
};

&tlmm {
	gpio-reserved-ranges = <36 4>, <74 1>;

	hall_sensor_default: hall-sensor-default-state {
		pins = "gpio66";
		function = "gpio";
		drive-strength = <2>;
		bias-disable;
		input-enable;
	};

	wcd_default: wcd-reset-n-active-state {
		pins = "gpio107";
		function = "gpio";
		drive-strength = <16>;
		bias-disable;
		output-low;
	};

	tdm1_active: tdm1-active-state {
		clk-pins {
			pins = "gpio121";
			function = "i2s1_sck";
			drive-strength = <6>;
			bias-disable;
			output-high;
		};

		data0-pins {
			pins = "gpio122";
			function = "i2s1_data0";
			drive-strength = <6>;
			bias-disable;
		};

		ws-pins {
			pins = "gpio123";
			function = "i2s1_ws";
			drive-strength = <6>;
			bias-disable;
			output-high;
		};

		data1-pins {
			pins = "gpio124";
			function = "i2s1_data1";
			drive-strength = <6>;
			bias-pull-down;
		};
	};

	tdm1_sleep: tdm1-sleep-state {
		pins = "gpio121", "gpio122", "gpio123", "gpio124";
		function = "gpio";
		drive-strength = <2>;
		bias-pull-down;
		input-enable;
	};

	/* GPIO7 is the front SC820CS reset line on Caihong. */
	cam4_reset_active: cam4-reset-active-state {
		pins = "gpio7";
		function = "gpio";
		drive-strength = <2>;
		bias-disable;
	};

	cam4_reset_suspend: cam4-reset-suspend-state {
		pins = "gpio7";
		function = "gpio";
		drive-strength = <2>;
		bias-pull-down;
		output-low;
	};

	cam1_reset_active: cam1-reset-active-state {
		pins = "gpio82";
		function = "gpio";
		drive-strength = <2>;
		bias-disable;
	};

	cam1_reset_suspend: cam1-reset-suspend-state {
		pins = "gpio82";
		function = "gpio";
		drive-strength = <2>;
		bias-pull-down;
		output-low;
	};

	bt_default: bt-default-state {
		bt-en-pins {
			pins = "gpio17";
			function = "gpio";
			drive-strength = <16>;
			bias-disable;
		};

		sw-ctrl-pins {
			pins = "gpio18";
			function = "gpio";
			bias-pull-down;
		};
	};

	disp_reset_n_active: disp-reset-n-active-state {
		pins = "gpio133";
		function = "gpio";
		drive-strength = <8>;
		bias-disable;
	};

	mdp_vsync_active: mdp-vsync-active-state {
		pins = "gpio86";
		function = "mdp_vsync";
		drive-strength = <2>;
		bias-pull-down;
	};

	pogo_uart_default: pogo-uart-default-state {
		tx-pins {
			pins = "gpio62";
			function = "qup1_se7";
			drive-strength = <8>;
			bias-disable;
		};

		rx-pins {
			pins = "gpio63";
			function = "qup1_se7";
			drive-strength = <2>;
			bias-disable;
		};

		control-pins {
			pins = "gpio14", "gpio100";
			function = "gpio";
			drive-strength = <2>;
			bias-disable;
		};

		wake-pins {
			pins = "gpio137";
			function = "gpio";
			drive-strength = <2>;
			bias-pull-up;
			input-enable;
		};
	};

	ts_default: ts-default-state {
		pins = "gpio162";
		function = "gpio";
		drive-strength = <8>;
		bias-disable;
		input-enable;
	};

	wlan_en: wlan-en-state {
		pins = "gpio16";
		function = "gpio";
		drive-strength = <8>;
		bias-pull-down;
	};
};
&uart14 {
	status = "okay";

	bluetooth {
		compatible = "qcom,wcn7850-bt";

		vddrfacmn-supply = <&vreg_pmu_rfa_cmn>;
		vddaon-supply = <&vreg_pmu_aon_0p59>;
		vddwlcx-supply = <&vreg_pmu_wlcx_0p8>;
		vddwlmx-supply = <&vreg_pmu_wlmx_0p85>;
		vddrfa0p8-supply = <&vreg_pmu_rfa_0p8>;
		vddrfa1p2-supply = <&vreg_pmu_rfa_1p2>;
		vddrfa1p8-supply = <&vreg_pmu_rfa_1p8>;

		max-speed = <3200000>;
	};
};

&ufs_mem_hc {
	reset-gpios = <&tlmm 210 GPIO_ACTIVE_LOW>;

	vcc-supply = <&vreg_l17b_2p5>;
	vcc-max-microamp = <1300000>;
	vccq-supply = <&vreg_l1c_1p2>;
	vccq-max-microamp = <1200000>;

	status = "okay";
};

&ufs_mem_phy {
	vdda-phy-supply = <&vreg_l1d_0p88>;
	vdda-pll-supply = <&vreg_l3i_1p2>;

	status = "okay";
};

/*
 * DPAUX -> WCD9395 -> USB_SBU -> USB-C
 * eUSB2 DP/DM -> PM85550HS -> eUSB2 DP/DM -> USB-C
 * USB SS -> USB-C
 */

&usb_1 {
	dr_mode = "otg";
	usb-role-switch;

	status = "okay";
};

&usb_1_dwc3_hs {
	remote-endpoint = <&pmic_glink_hs_in>;
};

&usb_1_hsphy {
	vdd-supply = <&vreg_l1i_0p88>;
	vdda12-supply = <&vreg_l3i_1p2>;

	phys = <&pm8550b_eusb2_repeater>;

	status = "okay";
};

&usb_dp_qmpphy {
	vdda-phy-supply = <&vreg_l3i_1p2>;
	vdda-pll-supply = <&vreg_l3g_0p91>;

	status = "okay";
};

&usb_dp_qmpphy_out {
	remote-endpoint = <&pmic_glink_ss_in>;
};

&xo_board {
	clock-frequency = <76800000>;
};
